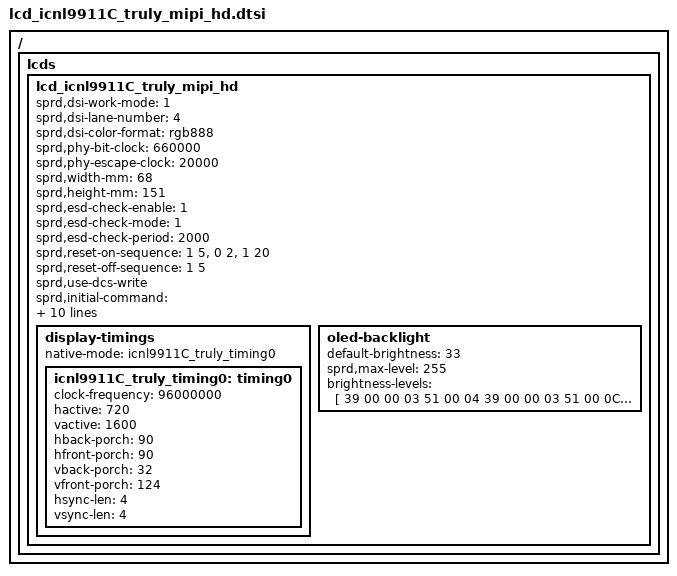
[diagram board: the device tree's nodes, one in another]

/*
 * R61350 Truly LCD config dtsi file for spreadtrum
 *
 * Copyright (C) 2018, Spreadtrum Communications Inc.
 *
 * SPDX-License-Identifier: (GPL-2.0+ OR MIT)
 */

/ {
	fragment {
		target-path = "/";
		__overlay__ {
			lcds {
				lcd_icnl9911C_truly_mipi_hd: lcd_icnl9911C_truly_mipi_hd {

					sprd,dsi-work-mode = <1>; /* video burst mode*/
					sprd,dsi-lane-number = <4>;
					sprd,dsi-color-format = "rgb888";

					sprd,phy-bit-clock = <660000>;	/* kbps */
					sprd,phy-escape-clock = <20000>;/* kHz */

					sprd,width-mm = <68>;
					sprd,height-mm = <151>;

					sprd,esd-check-enable = <1>;
					sprd,esd-check-mode = <1>;
					sprd,esd-check-period = <2000>;
					/* sprd,esd-check-register = <0x0A>; */
					/* sprd,esd-check-value = <0x9C>; */

					sprd,reset-on-sequence = <1 5>, <0 2>, <1 20>;
					sprd,reset-off-sequence = <1 5>;

					sprd,use-dcs-write;
					sprd,initial-command = [
						39 00 00 03 F0 5A 59
						39 00 00 03 F1 A5 A6
						39 00 00 1F B0 87 86 85 84 88 89 00 00 33 33 33 33 00 05 05 80 05 00 0F 05 04 03 02 01 02 03 04 00 00 00
						39 00 00 1E B1 53 43 85 00 00 05 05 80 05 00 04 08 54 00 00 00 44 40 02 01 40 02 01 40 02 01 40 02 01
						39 00 00 1D B5 08 00 00 c0 00 04 06 c1 c1 0C 0C 0E 0E 10 10 12 12 03 03 03 03 03 FF FF FC 00 00 00
						39 00 00 1D B4 09 00 00 c0 00 05 07 c1 c1 0D 0D 0F 0F 11 11 13 13 03 03 03 03 03 FF FF FC 00 00 00
						39 00 00 19 B8 00 00 00 00 00 00 00 00 00 00 00 00 00 00 00 00 00 00 00 00 00 00 00 00
						39 00 00 0E BB 01 05 09 11 0D 19 1D 55 25 69 00 21 25
						39 00 00 0F BC 00 00 00 00 02 20 FF 00 03 13 01 73 33 00
						39 00 00 0B BD E9 02 4F CF 72 A4 08 44 AE 15
						39 00 00 0B BE 73 73 50 32 0C 77 43 07 0E 0E
						39 00 00 09 BF 07 25 07 25 7F 00 11 04
						39 00 00 0A C0 10 FF FF FF FF FF 00 FF 00
						39 00 00 14 C1 C0 20 20 7C 04 5A 5A 04 2A 40 36 00 07 CF FF FF C0 00 C0
						15 00 00 02 C2 00
						39 00 00 0B C3 06 00 FF 00 FF 00 00 81 01 00
						39 00 00 0B C4 84 01 2B 41 00 3C 00 03 03 2E
						39 00 00 0C C5 03 1C C0 C0 40 10 42 44 0a 09 14
						39 00 00 0B C6 88 16 20 28 29 33 64 34 08 04
						15 00 00 02 CB 00
						39 00 00 06 D0 80 0D FF 0F 63
						15 00 00 02 D2 42
						39 00 00 18 E1 EF FE FE FE FE EE F0 20 33 FF 00 00 6A 90 C0 0D 6A F0 3E AC 00 07 D0
						39 00 00 1B E0 30 00 80 88 11 3F 22 62 DF A0 04 CC 01 FF F6 FF F0 FD FF FD F8 F5 FC FC FD FF
						39 00 00 1C EC 00 80 80 80 80 80 80 80 80 80 80 80 80 80 80 80 80 80 80 80 80 80 80 80 FF FF FF
						39 00 00 1C E9 11 30 00 02 23 23 23 23 23 23 23 23 23 23 23 23 23 23 15 B0 22 30 81 00 00 00 00
						39 00 00 03 F1 5A 59
						39 00 00 03 F0 A5 A6
						15 00 00 02 35 00

						15 00 00 02 53 2C
						15 00 00 02 55 00
						05 78 00 01 11
						05 14 00 01 29
						15 00 00 02 26 01
						];

					sprd,sleep-in-command = [
						15 00 00 02 26 08
						05 14 00 01 28
						05 78 00 01 10
						];

					sprd,sleep-out-command = [
						05 78 00 01 11
						05 14 00 01 29
						15 00 00 02 26 01
						];

					sprd,cabc-off-command = [
						23 00 00 02 55 00
						];
					sprd,cabc-ui-command = [
						23 00 00 02 55 01
						];
					sprd,cabc-still-image-command = [
						23 00 00 02 55 02
						];
					sprd,cabc-video-command = [
						23 00 00 02 55 03
						];


					display-timings {
						native-mode = <&icnl9911C_truly_timing0>;

						icnl9911C_truly_timing0: timing0 {
							clock-frequency = <96000000>;
							hactive = <720>;
							vactive = <1600>;
							hback-porch = <90>;
							hfront-porch = <90>;
							vback-porch = <32>;
							vfront-porch = <124>;
							hsync-len = <4>;
							vsync-len = <4>;
						};
					};

						oled-backlight {			
						default-brightness = <33>;	
						sprd,max-level = <255>;
						brightness-levels = [				
            		    	39 00 00 03 51 00 04
							39 00 00 03 51 00 0C
							39 00 00 03 51 00 14
							39 00 00 03 51 00 1C
							39 00 00 03 51 00 25
							39 00 00 03 51 00 2D
							39 00 00 03 51 00 35
							39 00 00 03 51 00 3D
							39 00 00 03 51 00 45
							39 00 00 03 51 00 4D
							39 00 00 03 51 00 55
							39 00 00 03 51 00 5D
							39 00 00 03 51 00 65
							39 00 00 03 51 00 6D
							39 00 00 03 51 00 75
							39 00 00 03 51 00 7D
							39 00 00 03 51 00 85
							39 00 00 03 51 00 8D
							39 00 00 03 51 00 95
							39 00 00 03 51 00 9D
							39 00 00 03 51 00 A5
							39 00 00 03 51 00 AD
							39 00 00 03 51 00 B5
							39 00 00 03 51 00 BD
							39 00 00 03 51 00 C5
							39 00 00 03 51 00 CD
							39 00 00 03 51 00 D5
							39 00 00 03 51 00 DD
							39 00 00 03 51 00 E5
							39 00 00 03 51 00 EE
							39 00 00 03 51 00 F6
							39 00 00 03 51 00 FE
							39 00 00 03 51 01 06
							39 00 00 03 51 01 0E
							39 00 00 03 51 01 16
							39 00 00 03 51 01 1E
							39 00 00 03 51 01 26
							39 00 00 03 51 01 2E
							39 00 00 03 51 01 36
							39 00 00 03 51 01 3E
							39 00 00 03 51 01 46
							39 00 00 03 51 01 4E
							39 00 00 03 51 01 56
							39 00 00 03 51 01 5E
							39 00 00 03 51 01 66
							39 00 00 03 51 01 6E
							39 00 00 03 51 01 76
							39 00 00 03 51 01 7E
							39 00 00 03 51 01 86
							39 00 00 03 51 01 8E
							39 00 00 03 51 01 96
							39 00 00 03 51 01 9E
							39 00 00 03 51 01 A6
							39 00 00 03 51 01 AE
							39 00 00 03 51 01 B7
							39 00 00 03 51 01 BF
							39 00 00 03 51 01 C7
							39 00 00 03 51 01 CF
							39 00 00 03 51 01 D7
							39 00 00 03 51 01 DF
							39 00 00 03 51 01 E7
							39 00 00 03 51 01 EF
							39 00 00 03 51 01 F7
							39 00 00 03 51 01 FF
							39 00 00 03 51 02 07
							39 00 00 03 51 02 0F
							39 00 00 03 51 02 17
							39 00 00 03 51 02 1F
							39 00 00 03 51 02 27
							39 00 00 03 51 02 2F
							39 00 00 03 51 02 37
							39 00 00 03 51 02 3F
							39 00 00 03 51 02 47
							39 00 00 03 51 02 4F
							39 00 00 03 51 02 57
							39 00 00 03 51 02 5F
							39 00 00 03 51 02 67
							39 00 00 03 51 02 6F
							39 00 00 03 51 02 77
							39 00 00 03 51 02 80
							39 00 00 03 51 02 88
							39 00 00 03 51 02 90
							39 00 00 03 51 02 98
							39 00 00 03 51 02 A0
							39 00 00 03 51 02 A8
							39 00 00 03 51 02 B0
							39 00 00 03 51 02 B8
							39 00 00 03 51 02 C0
							39 00 00 03 51 02 C8
							39 00 00 03 51 02 D0
							39 00 00 03 51 02 D8
							39 00 00 03 51 02 E0
							39 00 00 03 51 02 E8
							39 00 00 03 51 02 F0
							39 00 00 03 51 02 F8
							39 00 00 03 51 03 00
							39 00 00 03 51 03 08
							39 00 00 03 51 03 10
							39 00 00 03 51 03 18
							39 00 00 03 51 03 20
							39 00 00 03 51 03 28
							39 00 00 03 51 03 30
							39 00 00 03 51 03 38
							39 00 00 03 51 03 40
							39 00 00 03 51 03 49
							39 00 00 03 51 03 51
							39 00 00 03 51 03 59
							39 00 00 03 51 03 61
							39 00 00 03 51 03 69
							39 00 00 03 51 03 71
							39 00 00 03 51 03 79
							39 00 00 03 51 03 81
							39 00 00 03 51 03 89
							39 00 00 03 51 03 91
							39 00 00 03 51 03 99
							39 00 00 03 51 03 A1
							39 00 00 03 51 03 A9
							39 00 00 03 51 03 B1
							39 00 00 03 51 03 B9
							39 00 00 03 51 03 C1
							39 00 00 03 51 03 C9
							39 00 00 03 51 03 D1
							39 00 00 03 51 03 D9
							39 00 00 03 51 03 E1
							39 00 00 03 51 03 E9
							39 00 00 03 51 03 F1
							39 00 00 03 51 03 F9
							39 00 00 03 51 04 01
							39 00 00 03 51 04 09
							39 00 00 03 51 04 12
							39 00 00 03 51 04 1A
							39 00 00 03 51 04 22
							39 00 00 03 51 04 2A
							39 00 00 03 51 04 32
							39 00 00 03 51 04 3A
							39 00 00 03 51 04 42
							39 00 00 03 51 04 4A
							39 00 00 03 51 04 52
							39 00 00 03 51 04 5A
							39 00 00 03 51 04 62
							39 00 00 03 51 04 6A
							39 00 00 03 51 04 72
							39 00 00 03 51 04 7A
							39 00 00 03 51 04 82
							39 00 00 03 51 04 8A
							39 00 00 03 51 04 92
							39 00 00 03 51 04 9A
							39 00 00 03 51 04 A2
							39 00 00 03 51 04 AA
							39 00 00 03 51 04 B2
							39 00 00 03 51 04 BA
							39 00 00 03 51 04 C2
							39 00 00 03 51 04 CA
							39 00 00 03 51 04 D2
							39 00 00 03 51 04 DB
							39 00 00 03 51 04 E3
							39 00 00 03 51 04 EB
							39 00 00 03 51 04 F3
							39 00 00 03 51 04 FB
							39 00 00 03 51 05 03
							39 00 00 03 51 05 0B
							39 00 00 03 51 05 13
							39 00 00 03 51 05 1B
							39 00 00 03 51 05 23
							39 00 00 03 51 05 2B
							39 00 00 03 51 05 33
							39 00 00 03 51 05 3B
							39 00 00 03 51 05 43
							39 00 00 03 51 05 4B
							39 00 00 03 51 05 53
							39 00 00 03 51 05 5B
							39 00 00 03 51 05 63
							39 00 00 03 51 05 6B
							39 00 00 03 51 05 73
							39 00 00 03 51 05 7B
							39 00 00 03 51 05 83
							39 00 00 03 51 05 8B
							39 00 00 03 51 05 93
							39 00 00 03 51 05 9B
							39 00 00 03 51 05 A4
							39 00 00 03 51 05 AC
							39 00 00 03 51 05 B4
							39 00 00 03 51 05 BC
							39 00 00 03 51 05 C4
							39 00 00 03 51 05 CC
							39 00 00 03 51 05 D4
							39 00 00 03 51 05 DC
							39 00 00 03 51 05 E4
							39 00 00 03 51 05 EC
							39 00 00 03 51 05 F4
							39 00 00 03 51 05 FC
							39 00 00 03 51 06 04
							39 00 00 03 51 06 0C
							39 00 00 03 51 06 14
							39 00 00 03 51 06 1C
							39 00 00 03 51 06 24
							39 00 00 03 51 06 2C
							39 00 00 03 51 06 34
							39 00 00 03 51 06 3C
							39 00 00 03 51 06 44
							39 00 00 03 51 06 4C
							39 00 00 03 51 06 54
							39 00 00 03 51 06 5C
							39 00 00 03 51 06 64
							39 00 00 03 51 06 6D
							39 00 00 03 51 06 75
							39 00 00 03 51 06 7D
							39 00 00 03 51 06 85
							39 00 00 03 51 06 8D
							39 00 00 03 51 06 95
							39 00 00 03 51 06 9D
							39 00 00 03 51 06 A5
							39 00 00 03 51 06 AD
							39 00 00 03 51 06 B5
							39 00 00 03 51 06 BD
							39 00 00 03 51 06 C5
							39 00 00 03 51 06 CD
							39 00 00 03 51 06 D5
							39 00 00 03 51 06 DD
							39 00 00 03 51 06 E5
							39 00 00 03 51 06 ED
							39 00 00 03 51 06 F5
							39 00 00 03 51 06 FD
							39 00 00 03 51 07 05
							39 00 00 03 51 07 0D
							39 00 00 03 51 07 15
							39 00 00 03 51 07 1D
							39 00 00 03 51 07 25
							39 00 00 03 51 07 2D
							39 00 00 03 51 07 36
							39 00 00 03 51 07 3E
							39 00 00 03 51 07 46
							39 00 00 03 51 07 4E
							39 00 00 03 51 07 56
							39 00 00 03 51 07 5E
							39 00 00 03 51 07 66
							39 00 00 03 51 07 6E
							39 00 00 03 51 07 76
							39 00 00 03 51 07 7E
							39 00 00 03 51 07 86
							39 00 00 03 51 07 8E
							39 00 00 03 51 07 96
							39 00 00 03 51 07 9E
							39 00 00 03 51 07 A6
							39 00 00 03 51 07 AE
							39 00 00 03 51 07 B6
							39 00 00 03 51 07 BE
							39 00 00 03 51 07 C6
							39 00 00 03 51 07 CE
							39 00 00 03 51 07 D6
							39 00 00 03 51 07 DE
							39 00 00 03 51 07 E6
							39 00 00 03 51 07 EE
							39 00 00 03 51 07 F6
							39 00 00 03 51 07 FF
						];
					};
				};
			};
		};
	};
};
